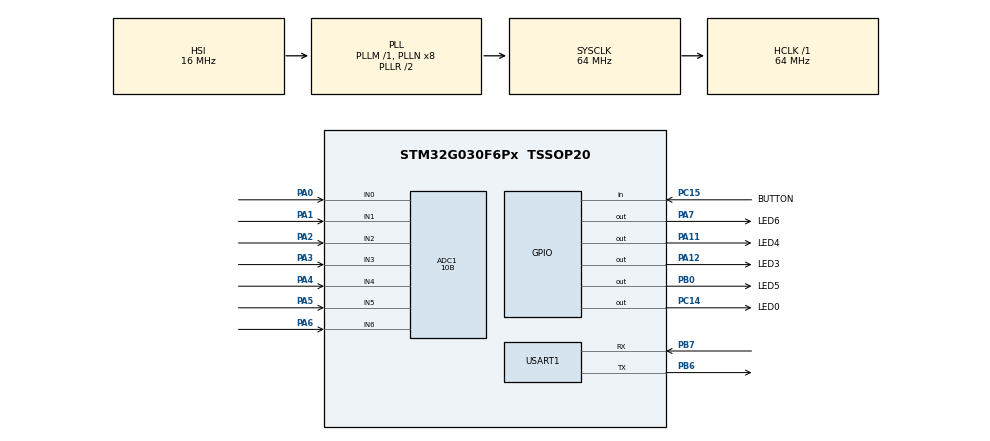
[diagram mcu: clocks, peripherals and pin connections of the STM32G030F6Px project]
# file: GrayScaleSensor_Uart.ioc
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ADC1.Channel-1\#ChannelRegularConversion=ADC_CHANNEL_0
ADC1.Channel-26\#ChannelRegularConversion=ADC_CHANNEL_1
ADC1.Channel-27\#ChannelRegularConversion=ADC_CHANNEL_2
ADC1.Channel-28\#ChannelRegularConversion=ADC_CHANNEL_3
ADC1.Channel-29\#ChannelRegularConversion=ADC_CHANNEL_4
ADC1.Channel-30\#ChannelRegularConversion=ADC_CHANNEL_5
ADC1.Channel-31\#ChannelRegularConversion=ADC_CHANNEL_6
ADC1.ContinuousConvMode=ENABLE
ADC1.DMAContinuousRequests=ENABLE
ADC1.EOCSelection=ADC_EOC_SINGLE_CONV
ADC1.EnableAnalogWatchDog1=false
ADC1.NbrOfConversion=7
ADC1.NbrOfConversionFlag=1
ADC1.Rank-1\#ChannelRegularConversion=1
ADC1.Rank-26\#ChannelRegularConversion=2
ADC1.Rank-27\#ChannelRegularConversion=3
ADC1.Rank-28\#ChannelRegularConversion=4
ADC1.Rank-29\#ChannelRegularConversion=5
ADC1.Rank-30\#ChannelRegularConversion=6
ADC1.Rank-31\#ChannelRegularConversion=7
ADC1.Resolution=ADC_RESOLUTION_10B
ADC1.SamplingTime-1\#ChannelRegularConversion=ADC_SAMPLINGTIME_COMMON_1
ADC1.SamplingTime-26\#ChannelRegularConversion=ADC_SAMPLINGTIME_COMMON_1
ADC1.SamplingTime-27\#ChannelRegularConversion=ADC_SAMPLINGTIME_COMMON_1
ADC1.SamplingTime-28\#ChannelRegularConversion=ADC_SAMPLINGTIME_COMMON_1
ADC1.SamplingTime-29\#ChannelRegularConversion=ADC_SAMPLINGTIME_COMMON_1
ADC1.SamplingTime-30\#ChannelRegularConversion=ADC_SAMPLINGTIME_COMMON_1
ADC1.SamplingTime-31\#ChannelRegularConversion=ADC_SAMPLINGTIME_COMMON_1
ADC1.SamplingTimeCommon1=ADC_SAMPLETIME_39CYCLES_5
ADC1.SamplingTimeCommon2=ADC_SAMPLETIME_39CYCLES_5
ADC1.SelectedChannel=ADC_CHANNEL_0|ADC_CHANNEL_1|ADC_CHANNEL_2|ADC_CHANNEL_3|ADC_CHANNEL_4|ADC_CHANNEL_5|ADC_CHANNEL_6
ADC1.TriggerFrequencyMode=ADC_TRIGGER_FREQ_LOW
ADC1.master=1
Dma.ADC1.0.Direction=DMA_PERIPH_TO_MEMORY
Dma.ADC1.0.EventEnable=DISABLE
Dma.ADC1.0.Instance=DMA1_Channel5
Dma.ADC1.0.MemDataAlignment=DMA_MDATAALIGN_WORD
Dma.ADC1.0.MemInc=DMA_MINC_ENABLE
Dma.ADC1.0.Mode=DMA_CIRCULAR
Dma.ADC1.0.PeriphDataAlignment=DMA_PDATAALIGN_WORD
Dma.ADC1.0.PeriphInc=DMA_PINC_DISABLE
Dma.ADC1.0.Polarity=HAL_DMAMUX_REQ_GEN_RISING
Dma.ADC1.0.Priority=DMA_PRIORITY_HIGH
Dma.ADC1.0.RequestNumber=1
Dma.ADC1.0.SignalID=NONE
Dma.ADC1.0.SyncEnable=DISABLE
Dma.ADC1.0.SyncPolarity=HAL_DMAMUX_SYNC_NO_EVENT
Dma.ADC1.0.SyncRequestNumber=1
Dma.ADC1.0.SyncSignalID=NONE
Dma.Request0=ADC1
Dma.Request1=USART1_RX
Dma.Request2=USART1_TX
Dma.USART1_RX.1.Direction=DMA_PERIPH_TO_MEMORY
Dma.USART1_RX.1.EventEnable=DISABLE
Dma.USART1_RX.1.Instance=DMA1_Channel1
Dma.USART1_RX.1.MemDataAlignment=DMA_MDATAALIGN_BYTE
Dma.USART1_RX.1.MemInc=DMA_MINC_ENABLE
Dma.USART1_RX.1.Mode=DMA_NORMAL
Dma.USART1_RX.1.PeriphDataAlignment=DMA_PDATAALIGN_BYTE
Dma.USART1_RX.1.PeriphInc=DMA_PINC_DISABLE
Dma.USART1_RX.1.Polarity=HAL_DMAMUX_REQ_GEN_RISING
Dma.USART1_RX.1.Priority=DMA_PRIORITY_LOW
Dma.USART1_RX.1.RequestNumber=1
Dma.USART1_RX.1.SignalID=NONE
Dma.USART1_RX.1.SyncEnable=DISABLE
Dma.USART1_RX.1.SyncPolarity=HAL_DMAMUX_SYNC_NO_EVENT
Dma.USART1_RX.1.SyncRequestNumber=1
Dma.USART1_RX.1.SyncSignalID=NONE
Dma.USART1_TX.2.Direction=DMA_MEMORY_TO_PERIPH
Dma.USART1_TX.2.EventEnable=DISABLE
Dma.USART1_TX.2.Instance=DMA1_Channel2
Dma.USART1_TX.2.MemDataAlignment=DMA_MDATAALIGN_BYTE
Dma.USART1_TX.2.MemInc=DMA_MINC_ENABLE
Dma.USART1_TX.2.Mode=DMA_NORMAL
Dma.USART1_TX.2.PeriphDataAlignment=DMA_PDATAALIGN_BYTE
Dma.USART1_TX.2.PeriphInc=DMA_PINC_DISABLE
Dma.USART1_TX.2.Polarity=HAL_DMAMUX_REQ_GEN_RISING
Dma.USART1_TX.2.Priority=DMA_PRIORITY_LOW
Dma.USART1_TX.2.RequestNumber=1
Dma.USART1_TX.2.SignalID=NONE
Dma.USART1_TX.2.SyncEnable=DISABLE
Dma.USART1_TX.2.SyncPolarity=HAL_DMAMUX_SYNC_NO_EVENT
Dma.USART1_TX.2.SyncRequestNumber=1
Dma.USART1_TX.2.SyncSignalID=NONE
Mcu.Family=STM32G0
Mcu.Name=STM32G030F6Px
Mcu.Package=TSSOP20
NVIC.DMA1_Ch4_5_DMAMUX1_OVR_IRQn=true\:0\:0\:false\:false\:true\:false\:true\:true
NVIC.DMA1_Channel1_IRQn=true\:0\:0\:false\:false\:true\:false\:true\:true
NVIC.DMA1_Channel2_3_IRQn=true\:0\:0\:false\:false\:true\:false\:true\:true
NVIC.USART1_IRQn=true\:0\:0\:false\:false\:true\:true\:true\:true
PA0.Mode=IN0
PA0.Signal=ADC1_IN0
PA1.Mode=IN1
PA1.Signal=ADC1_IN1
PA11\ [PA9].GPIO_Label=LED4
PA11\ [PA9].Signal=GPIO_Output
PA12\ [PA10].GPIO_Label=LED3
PA12\ [PA10].Signal=GPIO_Output
PA13.Mode=Serial_Wire
PA13.Signal=SYS_SWDIO
PA14-BOOT0.Mode=Serial_Wire
PA14-BOOT0.Signal=SYS_SWCLK
PA14-BOOT0__PA15.StandardMode=true
PA2.Mode=IN2
PA2.Signal=ADC1_IN2
PA3.Mode=IN3
PA3.Signal=ADC1_IN3
PA4.Mode=IN4
PA4.Signal=ADC1_IN4
PA5.Mode=IN5
PA5.Signal=ADC1_IN5
PA6.Mode=IN6
PA6.Signal=ADC1_IN6
PA7.GPIO_Label=LED6
PA7.Signal=GPIO_Output
PB0.GPIO_Label=LED5
PB0.Signal=GPIO_Output
PB0__PB1__PB2__PA8.StandardMode=true
PB3__PB4__PB5__PB6.StandardMode=true
PB6.Mode=Asynchronous
PB6.Signal=USART1_TX
PB7.Mode=Asynchronous
PB7.Signal=USART1_RX
PB7__PB8.StandardMode=true
PC14-OSC32_IN\ (PC14).GPIO_Label=LED0
PC14-OSC32_IN\ (PC14).Signal=GPIO_Output
PC14-OSC32_IN\ (PC14)__PB9.StandardMode=true
PC15-OSC32_OUT\ (PC15).GPIO_Label=BUTTON
PC15-OSC32_OUT\ (PC15).GPIO_PuPd=GPIO_PULLUP
PC15-OSC32_OUT\ (PC15).Signal=GPIO_Input
ProjectManager.HeapSize=0x200
ProjectManager.StackSize=0x400
ProjectManager.TargetToolchain=MDK-ARM V5.32
RCC.ADCFreq_Value=64000000
RCC.AHBFreq_Value=64000000
RCC.CortexFreq_Value=64000000
RCC.EXTERNAL_CLOCK_VALUE=12288000
RCC.HCLKFreq_Value=64000000
RCC.HSE_VALUE=8000000
RCC.HSI_VALUE=16000000
RCC.LSE_VALUE=32768
RCC.SYSCLKFreq_VALUE=64000000
RCC.SYSCLKSource=RCC_SYSCLKSOURCE_PLLCLK
RCC.VCOOutputFreq_Value=128000000
USART1.VirtualMode-Asynchronous=VM_ASYNC
board=custom

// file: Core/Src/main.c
/* USER CODE BEGIN Header */
/**
  ******************************************************************************
  * @file           : main.c
  * @brief          : Main program body
  ******************************************************************************
  * @attention
  *
  * Copyright (c) 2022 STMicroelectronics.
  * All rights reserved.
  *
  * This software is licensed under terms that can be found in the LICENSE file
  * in the root directory of this software component.
  * If no LICENSE file comes with this software, it is provided AS-IS.
  *
  ******************************************************************************
  */
/* USER CODE END Header */
#include "main.h"
#include "adc.h"
#include "dma.h"
#include "usart.h"
#include "gpio.h"

/* USER CODE BEGIN Includes */
#include "app_main.h"
/* USER CODE END Includes */

void SystemClock_Config(void);

int main(void)
{

  /* MCU Configuration--------------------------------------------------------*/

  /* Reset of all peripherals, Initializes the Flash interface and the Systick. */
  HAL_Init();

  /* Configure the system clock */
  SystemClock_Config();

  /* USER CODE BEGIN SysInit */
  MX_DMA_Init();
  /* USER CODE END SysInit */

  /* Initialize all configured peripherals */
  MX_GPIO_Init();
  MX_ADC1_Init();
  MX_DMA_Init();
  MX_USART1_UART_Init();
  /* USER CODE BEGIN 2 */
  app_main_init();
  /* USER CODE END 2 */

  /* Infinite loop */
  /* USER CODE BEGIN WHILE */
  while (1)
  {
    app_main_loop();
    /* USER CODE END WHILE */

  }
}

void SystemClock_Config(void)
{
  RCC_OscInitTypeDef RCC_OscInitStruct = {0};
  RCC_ClkInitTypeDef RCC_ClkInitStruct = {0};

  /** Configure the main internal regulator output voltage
  */
  HAL_PWREx_ControlVoltageScaling(PWR_REGULATOR_VOLTAGE_SCALE1);

  /** Initializes the RCC Oscillators according to the specified parameters
  * in the RCC_OscInitTypeDef structure.
  */
  RCC_OscInitStruct.OscillatorType = RCC_OSCILLATORTYPE_HSI;
  RCC_OscInitStruct.HSIState = RCC_HSI_ON;
  RCC_OscInitStruct.HSIDiv = RCC_HSI_DIV1;
  RCC_OscInitStruct.HSICalibrationValue = RCC_HSICALIBRATION_DEFAULT;
  RCC_OscInitStruct.PLL.PLLState = RCC_PLL_ON;
  RCC_OscInitStruct.PLL.PLLSource = RCC_PLLSOURCE_HSI;
  RCC_OscInitStruct.PLL.PLLM = RCC_PLLM_DIV1;
  RCC_OscInitStruct.PLL.PLLN = 8;
  RCC_OscInitStruct.PLL.PLLP = RCC_PLLP_DIV2;
  RCC_OscInitStruct.PLL.PLLR = RCC_PLLR_DIV2;
  if (HAL_RCC_OscConfig(&RCC_OscInitStruct) != HAL_OK)
  {
    Error_Handler();
  }

  /** Initializes the CPU, AHB and APB buses clocks
  */
  RCC_ClkInitStruct.ClockType = RCC_CLOCKTYPE_HCLK|RCC_CLOCKTYPE_SYSCLK
                              |RCC_CLOCKTYPE_PCLK1;
  RCC_ClkInitStruct.SYSCLKSource = RCC_SYSCLKSOURCE_PLLCLK;
  RCC_ClkInitStruct.AHBCLKDivider = RCC_SYSCLK_DIV1;
  RCC_ClkInitStruct.APB1CLKDivider = RCC_HCLK_DIV1;

  if (HAL_RCC_ClockConfig(&RCC_ClkInitStruct, FLASH_LATENCY_2) != HAL_OK)
  {
    Error_Handler();
  }
}

void Error_Handler(void)
{
  __disable_irq();
  while (1)
  {
  }
}
